# LPC55S16 register map
Vendor: nxp.com; File version: 1.0
CPU: CM33 r2p0, little endian, MPU, FPU, VTOR, 3 interrupt priority bits
Registers are 32-bit, read-write, reset 0x0 unless marked. A register's access mark holds for its fields unless they carry their own. Offsets are from the block's base; [hi:lo] are bit positions; {n}, {i} and the like mark numbered series; 'fields as' and 'values as' point back to an identical list.

## SYSCON
Base 0x40000000
0x00 MEMORYREMAP — Memory Remap control register
  [1:0] MAP — Select the location of the vector table :.
    0=ROM0 (Vector Table in ROM.); 1=RAM1 (Vector Table in RAM.); 2=FLASH0 (Vector Table in Flash.); 3=FLASH1 (Vector Table in Flash.)
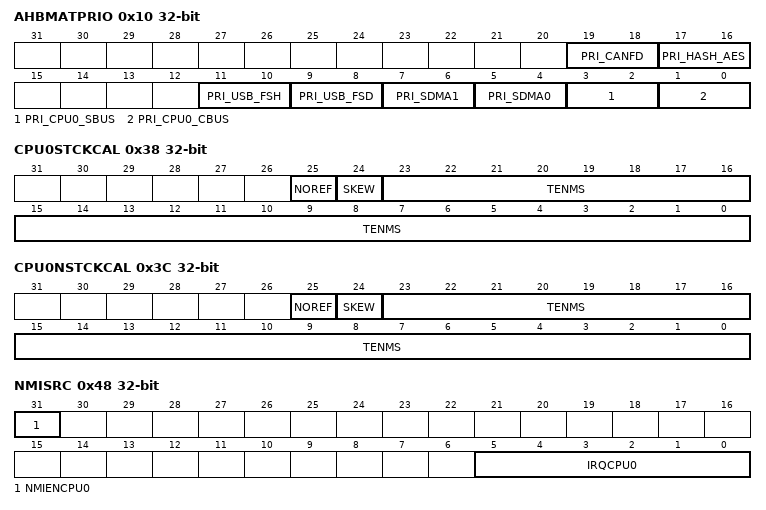
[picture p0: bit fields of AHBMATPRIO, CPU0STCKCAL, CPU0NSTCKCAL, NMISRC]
0x10 AHBMATPRIO — AHB Matrix priority control register Priority values are 3 = highest, 0 = lowest
  [19:18] PRI_CANFD — CANFD.
  [17:16] PRI_HASH_AES — HASH_AES.
  [11:10] PRI_USB_FSH — USB0-FS host.(USB0)
  [9:8] PRI_USB_FSD — USB0-FS Device.(USB0)
  [7:6] PRI_SDMA1 — DMA1 controller priority.
  [5:4] PRI_SDMA0 — DMA0 controller priority.
  [3:2] PRI_CPU0_SBUS — CPU0 S-AHB bus.
  [1:0] PRI_CPU0_CBUS — CPU0 C-AHB bus.
0x38 CPU0STCKCAL — System tick calibration for secure part of CPU0
  [25] NOREF — Indicates whether the device provides a reference clock to the processor: 0 = reference clock provided; 1 = no reference clock provided.
  [24] SKEW — Initial value for the Systick timer.
  [23:0] TENMS — Reload value for 10ms (100Hz) timing, subject to system clock skew errors. If the value reads as zero, the calibration value is not known.
0x3C CPU0NSTCKCAL — System tick calibration for non-secure part of CPU0
  [25] NOREF — Initial value for the Systick timer.
  [24] SKEW — Indicates whether the TENMS value is exact: 0 = TENMS value is exact; 1 = TENMS value is inexact, or not given.
  [23:0] TENMS — Reload value for 10 ms (100 Hz) timing, subject to system clock skew errors. If the value reads as zero, the calibration value is not known.
0x48 NMISRC — NMI Source Select
  [31] NMIENCPU0 — Write a 1 to this bit to enable the Non-Maskable Interrupt (NMI) source selected by IRQCPU0.
  [5:0] IRQCPU0 — The IRQ number of the interrupt that acts as the Non-Maskable Interrupt (NMI) for the CPU0, if enabled by NMIENCPU0.
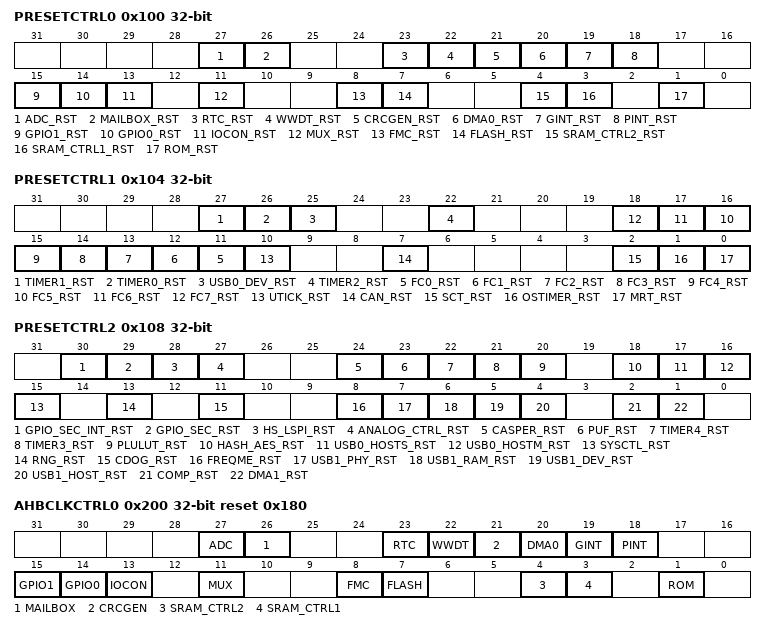
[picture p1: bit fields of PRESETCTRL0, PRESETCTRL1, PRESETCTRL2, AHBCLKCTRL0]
0x100 PRESETCTRL0 (PRESETCTRL view) — Peripheral reset control 0
  [all] fields
    0=RELEASED (Bloc is not reset.); 1=ASSERTED (Bloc is reset.)
  [27] ADC_RST — ADC reset control.
  [26] MAILBOX_RST — Inter CPU communication Mailbox reset control.
  [23] RTC_RST — Real Time Clock (RTC) reset control.
  [22] WWDT_RST — Watchdog Timer reset control.
  [21] CRCGEN_RST — CRCGEN reset control.
  [20] DMA0_RST — DMA0 reset control.
  [19] GINT_RST — Group interrupt (GINT) reset control.
  [18] PINT_RST — Pin interrupt (PINT) reset control.
  [15] GPIO1_RST — GPIO1 reset control.
  [14] GPIO0_RST — GPIO0 reset control.
  [13] IOCON_RST — I/O controller reset control.
  [11] MUX_RST — Input Mux reset control.
  [8] FMC_RST — FMC controller reset control.
  [7] FLASH_RST — Flash controller reset control.
  [4] SRAM_CTRL2_RST — SRAM Controller 2 reset control.
  [3] SRAM_CTRL1_RST — SRAM Controller 1 reset control.
  [1] ROM_RST — ROM reset control.
{0x100+4i} PRESETCTRLX{i} (PRESETCTRL view) (i=0..2) — Peripheral reset control register
  [31:0] DATA — Data array value
0x104 PRESETCTRL1 (reset mask 0xDE57FC47) (PRESETCTRL view) — Peripheral reset control 1
  [all] fields
    0=RELEASED (Bloc is not reset.); 1=ASSERTED (Bloc is reset.)
  [27] TIMER1_RST — Timer 1 reset control.
  [26] TIMER0_RST — Timer 0 reset control.
  [25] USB0_DEV_RST — USB0-FS DEV reset control.
  [22] TIMER2_RST — Timer 2 reset control.
  [n+11] FC{n}_RST (n=0..7) — FC{n} reset control.
  [10] UTICK_RST — UTICK reset control.
  [7] CAN_RST — CAN reset control.
  [2] SCT_RST — SCT reset control.
  [1] OSTIMER_RST — OS Event Timer reset control.
  [0] MRT_RST — MRT reset control.
0x108 PRESETCTRL2 (reset mask 0x7FFF77FE) (PRESETCTRL view) — Peripheral reset control 2
  [all] fields
    0=RELEASED (Bloc is not reset.); 1=ASSERTED (Bloc is reset.)
  [30] GPIO_SEC_INT_RST — GPIO secure int reset control.
  [29] GPIO_SEC_RST — GPIO secure reset control.
  [28] HS_LSPI_RST — HS LSPI reset control.
  [27] ANALOG_CTRL_RST — analog control reset control.
  [24] CASPER_RST — Casper reset control.
  [23] PUF_RST — PUF reset control reset control.
  [22] TIMER4_RST — Timer 4 reset control.
  [21] TIMER3_RST — Timer 3 reset control.
  [20] PLULUT_RST — PLU LUT reset control.
  [18] HASH_AES_RST — HASH_AES reset control.
  [17] USB0_HOSTS_RST — USB0-FS Host Slave reset control.
  [16] USB0_HOSTM_RST — USB0-FS Host Master reset control.
  [15] SYSCTL_RST — SYSCTL Block reset.
  [13] RNG_RST — RNG reset control.
  [11] CDOG_RST — Code Watchdog reset control.
  [8] FREQME_RST — Frequency meter reset control.
  [7] USB1_PHY_RST — USB1-HS PHY reset control.
  [6] USB1_RAM_RST — USB1-HS RAM reset control.
  [5] USB1_DEV_RST — USB1-HS dev reset control.
  [4] USB1_HOST_RST — USB1-HS Host reset control.
  [2] COMP_RST — Comparator reset control.
  [1] DMA1_RST — DMA1 reset control.
{0x120+4i} PRESETCTRLSET[{i}] (i=0..2) — Peripheral reset control set register
  [31:0] DATA — Data array value
{0x140+4i} PRESETCTRLCLR[{i}] (i=0..2) — Peripheral reset control clear register
  [31:0] DATA — Data array value
0x160 SWR_RESET wo — generate a software_reset
  [31:0] SWR_RESET — Write 0x5A00_0001 to generate a software_reset.
    0=RELEASED (Bloc is not reset.); 0x5A000001=ASSERTED (Generate a software reset.)
0x200 AHBCLKCTRL0 reset 0x180 (AHBCLKCTRL view) — AHB Clock control 0
  [all] fields
    0=DISABLE (Disable Clock.); 1=ENABLE (Enable Clock.)
  [27] ADC — Enables the clock for the ADC.
  [26] MAILBOX — Enables the clock for the Inter CPU communication Mailbox.
  [23] RTC — Enables the clock for the Real Time Clock (RTC).
  [22] WWDT — Enables the clock for the Watchdog Timer.
  [21] CRCGEN — Enables the clock for the CRCGEN.
  [20] DMA0 — Enables the clock for the DMA0.
  [19] GINT — Enables the clock for the Group interrupt (GINT).
  [18] PINT — Enables the clock for the Pin interrupt (PINT).
  [15] GPIO1 — Enables the clock for the GPIO1.
  [14] GPIO0 — Enables the clock for the GPIO0.
  [13] IOCON — Enables the clock for the I/O controller.
  [11] MUX — Enables the clock for the Input Mux.
  [8] FMC — Enables the clock for the FMC controller.
  [7] FLASH — Enables the clock for the Flash controller.
  [4] SRAM_CTRL2 — Enables the clock for the SRAM Controller 2.
  [3] SRAM_CTRL1 — Enables the clock for the SRAM Controller 1.
  [1] ROM — Enables the clock for the ROM.
{0x200+4i} AHBCLKCTRLX{i} (AHBCLKCTRL view) (i=0..2) — Peripheral reset control register
  [31:0] DATA — Data array value
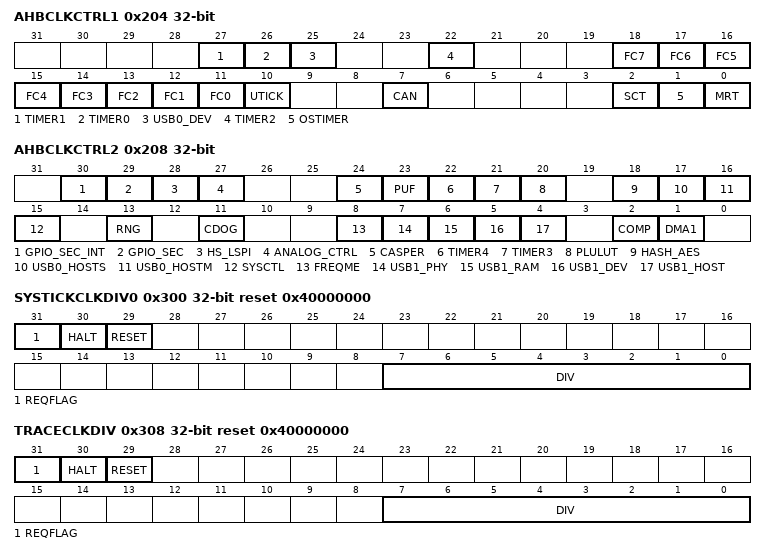
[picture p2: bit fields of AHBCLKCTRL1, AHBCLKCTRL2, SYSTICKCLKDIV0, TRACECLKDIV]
0x204 AHBCLKCTRL1 (reset mask 0xDE57FC47) (AHBCLKCTRL view) — AHB Clock control 1
  [all] fields
    0=DISABLE (Disable Clock.); 1=ENABLE (Enable Clock.)
  [27] TIMER1 — Enables the clock for the Timer 1.
  [26] TIMER0 — Enables the clock for the Timer 0.
  [25] USB0_DEV — Enables the clock for the USB0-FS device.
  [22] TIMER2 — Enables the clock for the Timer 2.
  [n+11] FC{n} (n=0..7) — Enables the clock for the FC{n}.
  [10] UTICK — Enables the clock for the UTICK.
  [7] CAN — Enables the clock for the CAN.
  [2] SCT — Enables the clock for the SCT.
  [1] OSTIMER — Enables the clock for the OS Event Timer.
  [0] MRT — Enables the clock for the MRT.
0x208 AHBCLKCTRL2 (reset mask 0x7FFF77FE) (AHBCLKCTRL view) — AHB Clock control 2
  [all] fields
    0=DISABLE (Disable Clock.); 1=ENABLE (Enable Clock.)
  [30] GPIO_SEC_INT — Enables the clock for the GPIO secure int.
  [29] GPIO_SEC — Enables the clock for the GPIO secure.
  [28] HS_LSPI — Enables the clock for the HS LSPI.
  [27] ANALOG_CTRL — Enables the clock for the analog control.
  [24] CASPER — Enables the clock for the Casper.
  [23] PUF — Enables the clock for the PUF reset control.
  [22] TIMER4 — Enables the clock for the Timer 4.
  [21] TIMER3 — Enables the clock for the Timer 3.
  [20] PLULUT — Enables the clock for the PLU LUT.
  [18] HASH_AES — Enables the clock for the HASH_AES.
  [17] USB0_HOSTS — Enables the clock for the USB0-FS Host Slave.
  [16] USB0_HOSTM — Enables the clock for the USB0-FS Host Master.
  [15] SYSCTL — SYSCTL block clock.
  [13] RNG — Enables the clock for the RNG.
  [11] CDOG — Enables the clock for the code watchdog.
  [8] FREQME — Enables the clock for the Frequency meter.
  [7] USB1_PHY — Enables the clock for the USB1-HS PHY.
  [6] USB1_RAM — Enables the clock for the USB1-HS RAM.
  [5] USB1_DEV — Enables the clock for the USB1-HS device.
  [4] USB1_HOST — Enables the clock for the USB1-HS Host.
  [2] COMP — Enables the clock for the Comparator.
  [1] DMA1 — Enables the clock for the DMA1.
{0x220+4i} AHBCLKCTRLSET[{i}] (i=0..2) — Peripheral reset control register
  [31:0] DATA — Data array value
{0x240+4i} AHBCLKCTRLCLR[{i}] (i=0..2) — Peripheral reset control register
  [31:0] DATA — Data array value
0x260 SYSTICKCLKSEL0 reset 0x7 (SYSTICKCLKSEL view) — System Tick Timer for CPU0 source select
  [2:0] SEL — System Tick Timer for CPU0 source select.
    0=ENUM_0x0 (System Tick 0 divided clock.); 1=ENUM_0x1 (FRO 1MHz clock.); 2=ENUM_0x2 (Oscillator 32 kHz clock.); {v}=ENUM_{0x0+v} (No clock.) (v=3..7)
0x260 SYSTICKCLKSELX0 (SYSTICKCLKSEL view) — Peripheral reset control register
  [31:0] DATA — Data array value
0x268 TRACECLKSEL reset 0x7 — Trace clock source select
  [2:0] SEL — Trace clock source select.
    0=ENUM_0x0 (Trace divided clock.); 1=ENUM_0x1 (FRO 1MHz clock.); 2=ENUM_0x2 (Oscillator 32 kHz clock.); {v}=ENUM_{0x0+v} (No clock.) (v=3..7)
{0x26C+4i} CTIMERCLKSEL{i} reset 0x7 (CTIMERCLKSEL view) (i=0..4) — CTimer {i} clock source select
  [2:0] SEL — CTimer {i} clock source select.
    0=ENUM_0x0 (Main clock.); 1=ENUM_0x1 (PLL0 clock.); 2=ENUM_0x2 (No clock.); 3=ENUM_0x3 (FRO 96 MHz clock.); 4=ENUM_0x4 (FRO 1MHz clock.); 5=ENUM_0x5 (MCLK clock.); 6=ENUM_0x6 (Oscillator 32kHz clock.); 7=ENUM_0x7 (No clock.)
{0x26C+4i} CTIMERCLKSELX{i} (CTIMERCLKSEL view) (i=0..4) — Peripheral reset control register
  [31:0] DATA — Data array value
0x280 MAINCLKSELA — Main clock A source select
  [2:0] SEL — Main clock A source select.
    0=ENUM_0x0 (FRO 12 MHz clock.); 1=ENUM_0x1 (CLKIN clock.); 2=ENUM_0x2 (FRO 1MHz clock.); 3=ENUM_0x3 (FRO 96 MHz clock.)
0x284 MAINCLKSELB — Main clock source select
  [2:0] SEL — Main clock source select.
    0=ENUM_0x0 (Main Clock A.); 1=ENUM_0x1 (PLL0 clock.); 2=ENUM_0x2 (PLL1 clock.); 3=ENUM_0x3 (Oscillator 32 kHz clock.)
0x288 CLKOUTSEL reset 0xF — CLKOUT clock source select
  [3:0] SEL — CLKOUT clock source select.
    0=ENUM_0x0 (Main clock.); 1=ENUM_0x1 (PLL0 clock.); 2=ENUM_0x2 (CLKIN clock.); 3=ENUM_0x3 (FRO 96 MHz clock.); 4=ENUM_0x4 (FRO 1MHz clock.); 5=ENUM_0x5 (PLL1 clock.); 6=ENUM_0x6 (Oscillator 32kHz clock.); 7=ENUM_0x7 (No clock.); {v}=ENUM_{0x0+v} (No clock.) (v=12..15)
0x290 PLL0CLKSEL reset 0x7 — PLL0 clock source select
  [2:0] SEL — PLL0 clock source select.
    0=ENUM_0x0 (FRO 12 MHz clock.); 1=ENUM_0x1 (CLKIN clock.); 2=ENUM_0x2 (FRO 1MHz clock.); 3=ENUM_0x3 (Oscillator 32kHz clock.); {v}=ENUM_{0x0+v} (No clock.) (v=4..7)
0x294 PLL1CLKSEL reset 0x7 — PLL1 clock source select
  [2:0] SEL — PLL1 clock source select.
    values as PLL0CLKSEL.SEL
0x2A0 CANCLKSEL reset 0x7 — CAN clock source select
  [2:0] SEL — CAN clock source select.
    0=ENUM_0x0 (CAN divided clock.); 1=ENUM_0x1 (FRO 1MHz clock.); 2=ENUM_0x2 (Oscillator 32 kHz clock.); {v}=ENUM_{0x0+v} (No clock.) (v=3..7)
0x2A4 ADCCLKSEL reset 0x7 — ADC clock source select
  [2:0] SEL — ADC clock source select.
    0=ENUM_0x0 (Main clock.); 1=ENUM_0x1 (PLL0 clock.); 2=ENUM_0x2 (FRO 96 MHz clock.); 4=ENUM_0x4 (Xtal clock coming directly.); 5=ENUM_0x5 (No clock.); 6=ENUM_0x6 (No clock.); 7=ENUM_0x7 (No clock.)
0x2A8 USB0CLKSEL reset 0x7 — FS USB clock source select
  [2:0] SEL — FS USB clock source select.
    0=ENUM_0x0 (Main clock.); 1=ENUM_0x1 (PLL0 clock.); 2=ENUM_0x2 (No clock.); 3=ENUM_0x3 (FRO 96 MHz clock.); 4=ENUM_0x4 (No clock.); 5=ENUM_0x5 (PLL1 clock.); 6=ENUM_0x6 (No clock.); 7=ENUM_0x7 (No clock.)
0x2AC CLK32KCLKSEL — clock low speed source select for HS USB.
  [3] SEL
    0=ENUM_0x0 (Oscillator 32 kHz clock.); 1=ENUM_0x1 (FRO1MHz_divided clock.)
{0x2B0+4i} FCCLKSEL{i} reset 0x7 (FCCLKSEL view) (i=0..7) — Flexcomm Interface {i} clock source select for Fractional Rate Divider
  [2:0] SEL — Flexcomm Interface {i} clock source select for Fractional Rate Divider.
    0=ENUM_0x0 (Main clock.); 1=ENUM_0x1 (system PLL divided clock.); 2=ENUM_0x2 (FRO 12 MHz clock.); 3=ENUM_0x3 (FRO 96 MHz clock.); 4=ENUM_0x4 (FRO 1MHz clock.); 5=ENUM_0x5 (MCLK clock.); 6=ENUM_0x6 (Oscillator 32 kHz clock.); 7=ENUM_0x7 (No clock.)
{0x2B0+4i} FCCLKSELX{i} (FCCLKSEL view) (i=0..7) — Peripheral reset control register
  [31:0] DATA — Data array value
0x2D0 HSLSPICLKSEL reset 0x7 — HS LSPI clock source select
  [2:0] SEL — HS LSPI clock source select.
    0=ENUM_0x0 (Main clock.); 1=ENUM_0x1 (system PLL divided clock.); 2=ENUM_0x2 (FRO 12 MHz clock.); 3=ENUM_0x3 (FRO 96 MHz clock.); 4=ENUM_0x4 (FRO 1MHz clock.); 5=ENUM_0x5 (No clock.); 6=ENUM_0x6 (Oscillator 32 kHz clock.); 7=ENUM_0x7 (No clock.)
0x2E0 MCLKCLKSEL reset 0x7 — MCLK clock source select
  [2:0] SEL — MCLK clock source select.
    0=ENUM_0x0 (FRO 96 MHz clock.); 1=ENUM_0x1 (PLL0 clock.); {v}=ENUM_{0x0+v} (No clock.) (v=4..7)
0x2F0 SCTCLKSEL reset 0x7 — SCTimer/PWM clock source select
  [2:0] SEL — SCTimer/PWM clock source select.
    0=ENUM_0x0 (Main clock.); 1=ENUM_0x1 (PLL0 clock.); 2=ENUM_0x2 (CLKIN clock.); 3=ENUM_0x3 (FRO 96 MHz clock.); 4=ENUM_0x4 (No clock.); 5=ENUM_0x5 (MCLK clock.); 6=ENUM_0x6 (No clock.); 7=ENUM_0x7 (No clock.)
0x300 SYSTICKCLKDIV0 reset 0x40000000 — System Tick Timer divider for CPU0
  [31] REQFLAG ro — Divider status flag.
    0=STABLE (Divider clock is stable.); 1=ONGOING (Clock frequency is not stable.)
  [30] HALT — Halts the divider counter.
    0=RUN (Divider clock is running.); 1=HALT (Divider clock is stoped.)
  [29] RESET wo — Resets the divider counter.
    0=RELEASED (Divider is not reset.); 1=ASSERTED (Divider is reset.)
  [7:0] DIV — Clock divider value.
0x308 TRACECLKDIV reset 0x40000000 — TRACE clock divider
  fields as SYSTICKCLKDIV0
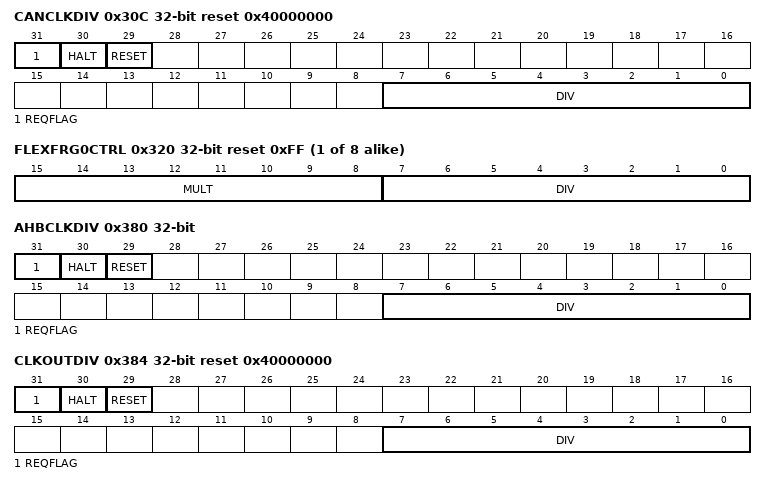
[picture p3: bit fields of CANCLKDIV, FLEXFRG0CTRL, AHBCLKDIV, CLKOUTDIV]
0x30C CANCLKDIV reset 0x40000000 — CAN clock divider
  fields as SYSTICKCLKDIV0
{0x320+4i} FLEXFRG{i}CTRL reset 0xFF (FLEXFRGCTRL view) (i=0..7) — Fractional rate divider for flexcomm {i}
  [15:8] MULT — Numerator of the fractional rate divider.
  [7:0] DIV — Denominator of the fractional rate divider.
{0x320+4i} FLEXFRGXCTRL{i} (FLEXFRGCTRL view) (i=0..7) — Peripheral reset control register
  [31:0] DATA — Data array value
0x380 AHBCLKDIV — System clock divider
  fields as SYSTICKCLKDIV0
0x384 CLKOUTDIV reset 0x40000000 — CLKOUT clock divider
  fields as SYSTICKCLKDIV0
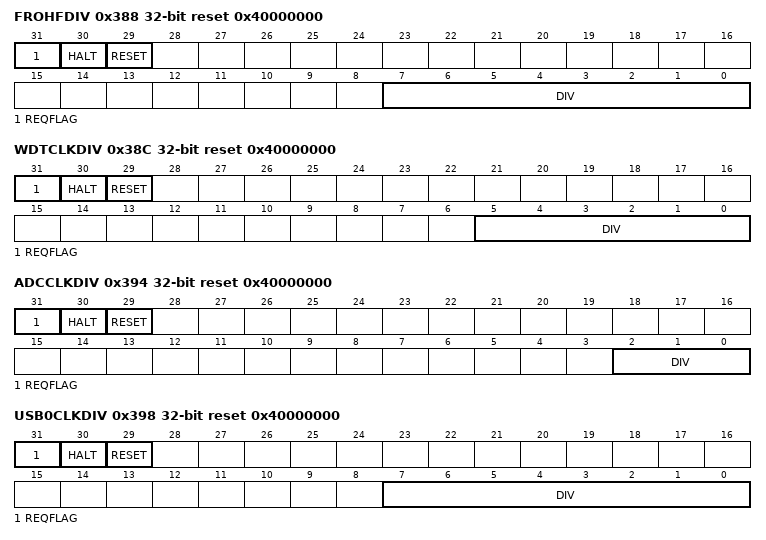
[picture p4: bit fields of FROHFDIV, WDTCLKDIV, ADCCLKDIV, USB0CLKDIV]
0x388 FROHFDIV reset 0x40000000 — FRO_HF (96MHz) clock divider
  fields as SYSTICKCLKDIV0
0x38C WDTCLKDIV reset 0x40000000 — WDT clock divider
  [31] REQFLAG ro — Divider status flag.
    values as SYSTICKCLKDIV0.REQFLAG
  [30] HALT — Halts the divider counter.
    values as SYSTICKCLKDIV0.HALT
  [29] RESET wo — Resets the divider counter.
    values as SYSTICKCLKDIV0.RESET
  [5:0] DIV — Clock divider value.
0x394 ADCCLKDIV reset 0x40000000 — ADC clock divider
  [31] REQFLAG ro — Divider status flag.
    values as SYSTICKCLKDIV0.REQFLAG
  [30] HALT — Halts the divider counter.
    values as SYSTICKCLKDIV0.HALT
  [29] RESET wo — Resets the divider counter.
    values as SYSTICKCLKDIV0.RESET
  [2:0] DIV — Clock divider value.
0x398 USB0CLKDIV reset 0x40000000 — USB0-FS Clock divider
  fields as SYSTICKCLKDIV0
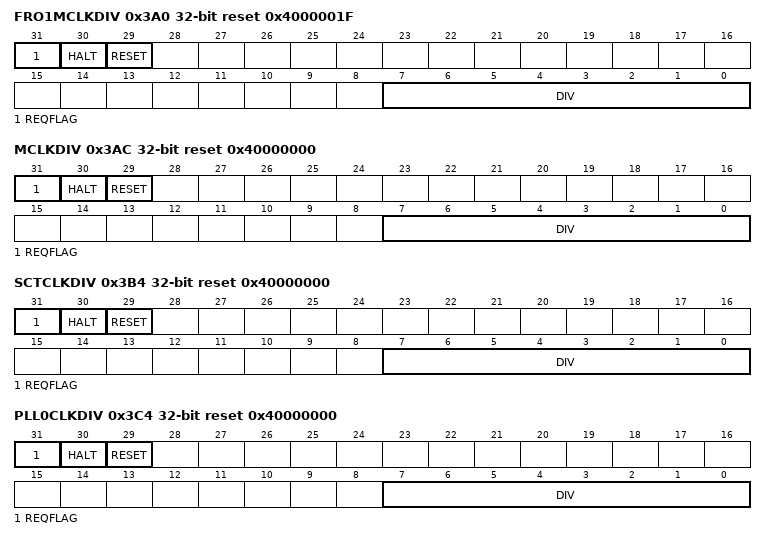
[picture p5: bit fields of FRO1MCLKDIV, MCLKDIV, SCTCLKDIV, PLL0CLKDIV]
0x3A0 FRO1MCLKDIV reset 0x4000001F — FRO1MHz Clock divider (FRO1M_divided)
  fields as SYSTICKCLKDIV0
0x3AC MCLKDIV reset 0x40000000 — I2S MCLK clock divider
  fields as SYSTICKCLKDIV0
0x3B4 SCTCLKDIV reset 0x40000000 — SCT/PWM clock divider
  fields as SYSTICKCLKDIV0
0x3C4 PLL0CLKDIV reset 0x40000000 — PLL0 clock divider
  fields as SYSTICKCLKDIV0
0x3FC CLOCKGENUPDATELOCKOUT — Control clock configuration registers access (like xxxDIV, xxxSEL)
  [31:0] CLOCKGENUPDATELOCKOUT — Control clock configuration registers access (for example, xxxDIV, xxxSEL).
    0=FREEZE (all hardware clock configruration are freeze.); 1=ENABLE (update all clock configuration.)
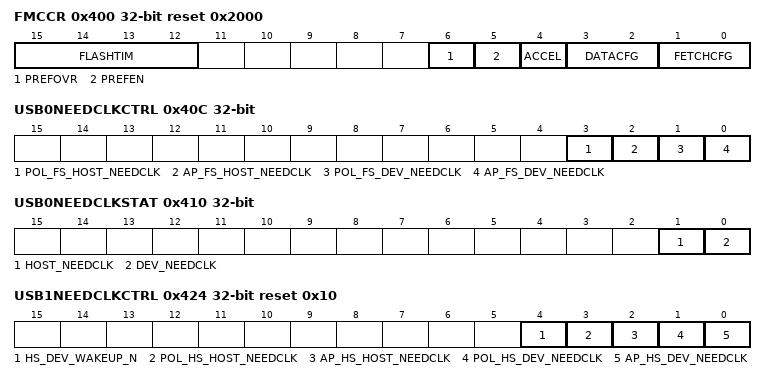
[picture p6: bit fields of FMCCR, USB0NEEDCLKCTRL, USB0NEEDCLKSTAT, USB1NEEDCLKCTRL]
0x400 FMCCR reset 0x2000 — FMC configuration register
  [15:12] FLASHTIM — Flash memory access time.
    0=1 system clock flash access time (for system clock rates up to 11 MHz); 1=2 system clocks flash access time (for system clock rates up to 22 MHz); 2=3 system clocks flash access time (for system clock rates up to 33 MHz); 3=4 system clocks flash access time (for system clock rates up to 44 MHz); 4=5 system clocks flash access time (for system clock rates up to 55 MHz); 5=6 system clocks flash access time (for system clock rates up to 66 MHz); 6=7 system clocks flash access time (for system clock rates up to 84 MHz); 7=8 system clocks flash access time (for system clock rates up to 104 MHz); 8=9 system clocks flash access time (for system clock rates up to 119 MHz); 9=10 system clocks flash access time (for system clock rates up to 129 MHz); 10=11 system clocks flash access time (for system clock rates up to 144 MHz); 11=12 system clocks flash access time (for system clock rates up to 150 MHz)
  [6] PREFOVR — Prefetch override.
    0=NORMAL (Any previously initiated prefetch will be completed.); 1=OVERRIDE (Any previously initiated prefetch will be aborted, and the next flash line following the current execution address will be prefetched if not already buffered.)
  [5] PREFEN — Prefetch enable.
    0=DISABLE (No instruction prefetch is performed.); 1=ENABLE (Instruction prefetch is enabled.)
  [4] ACCEL — Acceleration enable.
    0=DISABLE (Flash acceleration is disabled.); 1=ENABLE (Flash acceleration is enabled.)
  [3:2] DATACFG — Data read configuration.
    0=NOBUF (Data accesses from flash are not buffered.); 1=ONEBUF (One buffer is used for all data accesses.); 2=ALLBUF (All buffers can be used for data accesses.)
  [1:0] FETCHCFG — Instruction fetch configuration.
    0=NOBUF (Instruction fetches from flash are not buffered.); 1=ONEBUF (One buffer is used for all instruction fetches.); 2=ALLBUF (All buffers may be used for instruction fetches.)
0x40C USB0NEEDCLKCTRL — USB0-FS need clock control
  [3] POL_FS_HOST_NEEDCLK — USB0-FS Host USB0_NEEDCLK polarity for triggering the USB0-FS wake-up interrupt:.
    0=FALLING (Falling edge of device USB0_NEEDCLK triggers wake-up.); 1=RISING (Rising edge of device USB0_NEEDCLK triggers wake-up.)
  [2] AP_FS_HOST_NEEDCLK — USB0-FS Host USB0_NEEDCLK signal control:.
    0=HW_CTRL (Under hardware control.); 1=FORCED (Forced high.)
  [1] POL_FS_DEV_NEEDCLK — USB0-FS Device USB0_NEEDCLK polarity for triggering the USB0-FS wake-up interrupt:.
    values as POL_FS_HOST_NEEDCLK
  [0] AP_FS_DEV_NEEDCLK — USB0-FS Device USB0_NEEDCLK signal control:.
    0=HW_CTRL (Under hardware control.); 1=FORCED (Forced high.)
0x410 USB0NEEDCLKSTAT — USB0-FS need clock status
  [1] HOST_NEEDCLK ro — USB0-FS Host USB0_NEEDCLK signal status:.
    0=LOW (USB0-FS Host clock is low.); 1=HIGH (USB0-FS Host clock is high.)
  [0] DEV_NEEDCLK ro — USB0-FS Device USB0_NEEDCLK signal status:.
    0=LOW (USB0-FS Device clock is low.); 1=HIGH (USB0-FS Device clock is high.)
0x41C FMCFLUSH wo — FMCflush control
  [0] FLUSH — Flush control
    0=NO_FLUSH (No action is performed.); 1=FLUSH (Flush the FMC buffer contents.)
0x420 MCLKIO — MCLK control
  [0] MCLKIO — MCLK control.
    0=INPUT (input mode.); 1=OUTPUT (output mode.)
0x424 USB1NEEDCLKCTRL reset 0x10 — USB1-HS need clock control
  [4] HS_DEV_WAKEUP_N — Software override of device controller PHY wake up logic.
    0=FORCE_WUP (Forces USB1_PHY to wake-up.); 1=NORMAL_WUP (Normal USB1_PHY behavior.)
  [3] POL_HS_HOST_NEEDCLK — USB1-HS host need clock polarity for triggering the USB1_NEEDCLK wake-up interrupt.
    0=FALLING (Falling edge of HOST_NEEDCLK triggers wake-up.); 1=RISING (Rising edge of HOST_NEEDCLK triggers wake-up.)
  [2] AP_HS_HOST_NEEDCLK — USB1-HS Host need clock signal control:
    0=HW_CTRL (HOST_NEEDCLK is under hardware control.); 1=FORCED (HOST_NEEDCLK is forced high.)
  [1] POL_HS_DEV_NEEDCLK — USB1-HS device need clock polarity for triggering the USB1_NEEDCLK wake-up interrupt:
    0=FALLING (Falling edge of DEV_NEEDCLK triggers wake-up.); 1=RISING (Rising edge of DEV_NEEDCLK triggers wake-up.)
  [0] AP_HS_DEV_NEEDCLK — USB1-HS Device need_clock signal control:
    values as AP_HS_HOST_NEEDCLK
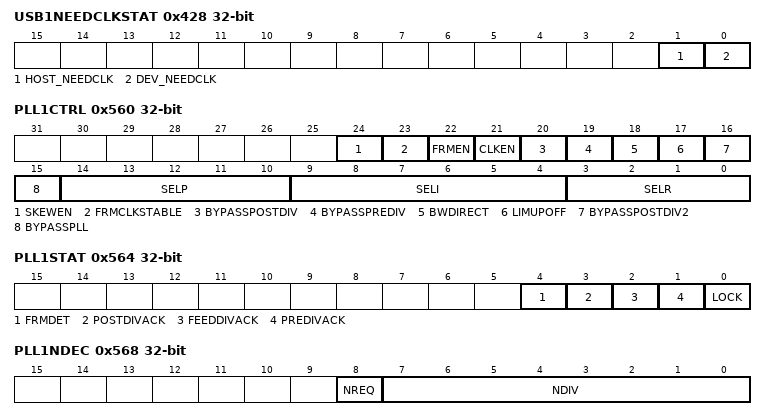
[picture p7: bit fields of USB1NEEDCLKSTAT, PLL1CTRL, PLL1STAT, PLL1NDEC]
0x428 USB1NEEDCLKSTAT — USB1-HS need clock status
  [1] HOST_NEEDCLK ro — USB1-HS Host need_clock signal status:.
    0=LOW (HOST_NEEDCLK is low.); 1=HIGH (HOST_NEEDCLK is high.)
  [0] DEV_NEEDCLK ro — USB1-HS Device need_clock signal status:.
    0=LOW (DEV_NEEDCLK is low.); 1=HIGH (DEV_NEEDCLK is high.)
0x440 FLASHREMAP_SIZE — This 32-bit register contains the size of the image to remap, in bytes. The 12 LSBs are ignored, so the size granularity is 4KB.
0x444 FLASHREMAP_SIZE_DP — This 32-bit register is a duplicate of FLASHREMAPSIZE for increased security.
  [31:0] FLASHREMAP_SIZE
0x448 FLASHREMAP_OFFSET — This 32-bit register contains the offset by which the image is to be remapped. The 12 LSBs are ignored, so the remap granularity is 4KB.
0x44C FLASHREMAP_OFFSET_DP — This 32-bit register is a duplicate of FLASHREMAPOFFSET for increased security.
  [31:0] FLASHREMAP_OFFSET
0x45C FLASHREMAP_LOCK reset 0xC33CA55A — Control write access to FLASHREMAP_SIZE and FLASHREMAP_OFFSET registers.
  [31:0] LOCK — Control write access to FLASHREMAP_SIZE and FLASHREMAP_OFFSET registers. Any value other than 0xC33CA55A and 0x3CC35AA5 does not modify the state.
    0x3CC35AA5=UNLOCK (Write access to 4 registers FLASHREMAP_SIZE* and FLASHREMAP_OFFSET* is unlocked.); 0xC33CA55A=LOCK (Write access to 4 registers FLASHREMAP_SIZE* and FLASHREMAP_OFFSET* is locked.)
0x470 CASPER_CTRL — Control CASPER integration.
  [0] INTERLEAVE — Control RAM access for RAMX0 and RAMX1.
    0=NORMAL (RAM access to RAMX0 and RAMX1 is consecutive.); 1=INTERLEAVE (RAM access to RAMX0 and RAMX1 is interleaved.)
0x560 PLL1CTRL — PLL1 550m control
  [24] SKEWEN — Skew mode.
    0=DISABLE (skewmode is disable.); 1=ENABLE (skewmode is enable.)
  [23] FRMCLKSTABLE — free running mode clockstable: Warning: Only make frm_clockstable = 1 after the PLL output frequency is stable.
  [22] FRMEN — 1: free running mode.
  [21] CLKEN — enable the output clock.
    0=DISABLE (Disable the output clock.); 1=ENABLE (Enable the output clock.)
  [20] BYPASSPOSTDIV — bypass of the post-divider.
    0=USED (use the post-divider.); 1=BYPASSED (bypass of the post-divider.)
  [19] BYPASSPREDIV — bypass of the pre-divider.
    0=USED (use the pre-divider.); 1=BYPASSED (bypass of the pre-divider.)
  [18] BWDIRECT — control of the bandwidth of the PLL.
    0=SYNC (the bandwidth is changed synchronously with the feedback-divider.); 1=DIRECT (modify the bandwidth of the PLL directly.)
  [17] LIMUPOFF — limup_off = 1 in spread spectrum and fractional PLL applications.
  [16] BYPASSPOSTDIV2 — bypass of the divide-by-2 divider in the post-divider.
    0=USED (use the divide-by-2 divider in the post-divider.); 1=BYPASSED (bypass of the divide-by-2 divider in the post-divider.)
  [15] BYPASSPLL — Bypass PLL input clock is sent directly to the PLL output (default).
    0=USED (use PLL.); 1=BYPASSED (PLL input clock is sent directly to the PLL output.)
  [14:10] SELP — Bandwidth select P value.
  [9:4] SELI — Bandwidth select I value.
  [3:0] SELR — Bandwidth select R value.
0x564 PLL1STAT — PLL1 550m status
  [4] FRMDET ro — free running detector output (active high).
  [3] POSTDIVACK ro — post-divider ratio change acknowledge.
  [2] FEEDDIVACK ro — feedback divider ratio change acknowledge.
  [1] PREDIVACK ro — pre-divider ratio change acknowledge.
  [0] LOCK ro — lock detector output (active high) Warning: The lock signal is only reliable between fref[2] :100 kHz to 20 MHz.
0x568 PLL1NDEC — PLL1 550m N divider
  [8] NREQ — pre-divider ratio change request.
  [7:0] NDIV — pre-divider divider ratio (N-divider).
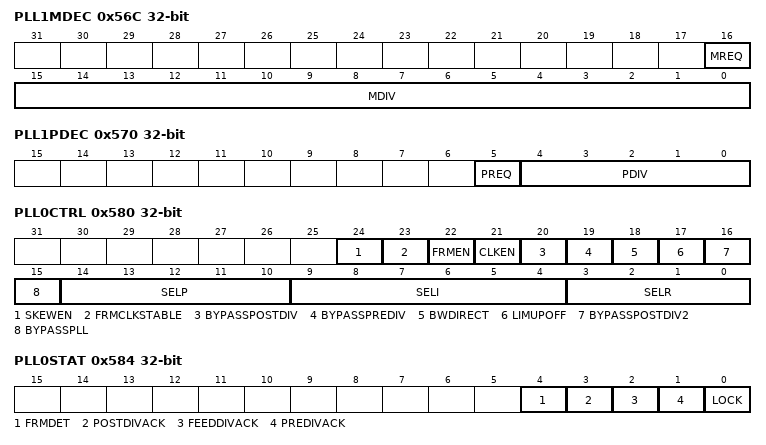
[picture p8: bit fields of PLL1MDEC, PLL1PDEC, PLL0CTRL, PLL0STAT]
0x56C PLL1MDEC — PLL1 550m M divider
  [16] MREQ — feedback ratio change request.
  [15:0] MDIV — feedback divider divider ratio (M-divider).
0x570 PLL1PDEC — PLL1 550m P divider
  [5] PREQ — feedback ratio change request.
  [4:0] PDIV — post-divider divider ratio (P-divider)
0x580 PLL0CTRL — PLL0 550m control
  [24] SKEWEN — skew mode.
    0=DISABLE (skew mode is disable.); 1=ENABLE (skew mode is enable.)
  [23] FRMCLKSTABLE — free running mode clockstable: Warning: Only make frm_clockstable =1 after the PLL output frequency is stable.
  [22] FRMEN — free running mode.
    0=DISABLE (free running mode is disable.); 1=ENABLE (free running mode is enable.)
  [21] CLKEN — enable the output clock.
    0=DISABLE (disable the output clock.); 1=ENABLE (enable the output clock.)
  [20] BYPASSPOSTDIV — bypass of the post-divider.
    values as PLL1CTRL.BYPASSPOSTDIV
  [19] BYPASSPREDIV — bypass of the pre-divider.
    values as PLL1CTRL.BYPASSPREDIV
  [18] BWDIRECT — Control of the bandwidth of the PLL.
    values as PLL1CTRL.BWDIRECT
  [17] LIMUPOFF — limup_off = 1 in spread spectrum and fractional PLL applications.
  [16] BYPASSPOSTDIV2 — bypass of the divide-by-2 divider in the post-divider.
    values as PLL1CTRL.BYPASSPOSTDIV2
  [15] BYPASSPLL — Bypass PLL input clock is sent directly to the PLL output (default).
    0=USED (use PLL.); 1=BYPASSED (Bypass PLL input clock is sent directly to the PLL output.)
  [14:10] SELP — Bandwidth select P value.
  [9:4] SELI — Bandwidth select I value.
  [3:0] SELR — Bandwidth select R value.
0x584 PLL0STAT — PLL0 550m status
  fields as PLL1STAT
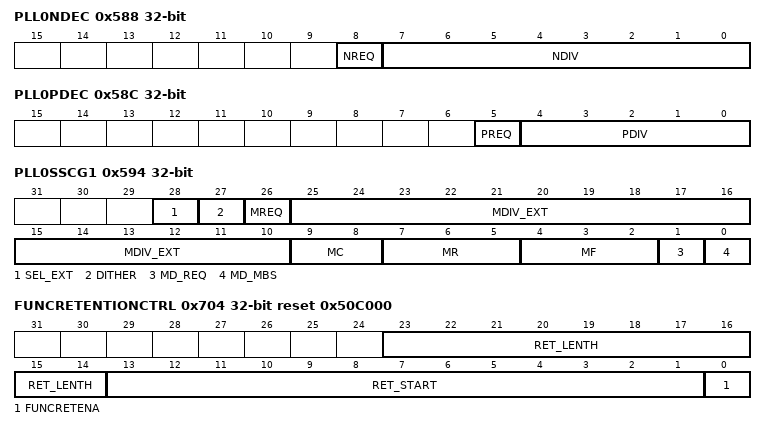
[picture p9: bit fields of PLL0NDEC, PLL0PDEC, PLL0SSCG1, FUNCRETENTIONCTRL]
0x588 PLL0NDEC — PLL0 550m N divider
  fields as PLL1NDEC
0x58C PLL0PDEC — PLL0 550m P divider
  fields as PLL1PDEC
0x590 PLL0SSCG0 — PLL0 Spread Spectrum Wrapper control register 0
  [31:0] MD_LBS — input word of the wrapper bit 31 to 0.
0x594 PLL0SSCG1 — PLL0 Spread Spectrum Wrapper control register 1
  [28] SEL_EXT — to select mdiv_ext and mreq_ext sel_ext = 0: mdiv ~ md[32:0], mreq = 1 sel_ext = 1 : mdiv = mdiv_ext, mreq = mreq_ext.
  [27] DITHER — dithering between two modulation frequencies in a random way or in a pseudo random way (white noise), in order to decrease the probability that the modulated waveform will occur with the same phase on a particular point on the screen.
  [26] MREQ — to select an external mreq value.
  [25:10] MDIV_EXT — to select an external mdiv value.
  [9:8] MC — modulation waveform control Compensation for low pass filtering of the PLL to get a triangular modulation at the output of the PLL, giving a flat frequency spectrum.
  [7:5] MR — programmable frequency modulation depth Dfmodpk-pk = Fref*kss/Fcco = kss/(2*md[32:25]dec) mr[2:0] = 000 => kss = 0 (no spread spectrum) mr[2:0] = 001 => kss ~ 1 mr[2:0] = 010 => kss ~ 1.
  [4:2] MF — programmable modulation frequency fm = Fref/Nss mf[2:0] = 000 => Nss=512 (fm ~ 3.
  [1] MD_REQ — md change request.
  [0] MD_MBS — input word of the wrapper bit 32.
0x704 FUNCRETENTIONCTRL reset 0x50C000 — Functional retention control register
  [23:14] RET_LENTH — lenth of Scan chains to save.
  [13:1] RET_START — Start address divided by 4 inside SRAMX bank.
  [0] FUNCRETENA — functional retention in power down only.
    0=DISABLE (disable functional retention.); 1=ENABLE (enable functional retention.)
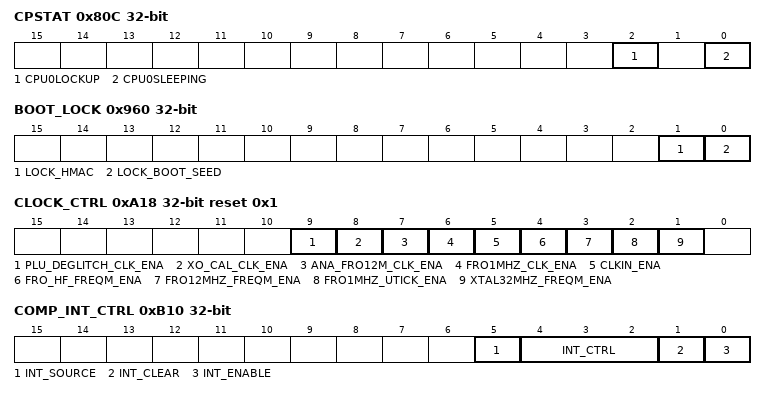
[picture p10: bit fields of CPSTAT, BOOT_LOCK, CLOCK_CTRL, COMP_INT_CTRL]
0x80C CPSTAT — CPU Status
  [2] CPU0LOCKUP ro — The CPU0 lockup state.
    0=AWAKE (the CPU is not in lockup.); 1=SLEEPING (the CPU is in lockup.)
  [0] CPU0SLEEPING ro — The CPU0 sleeping state.
    0=AWAKE (the CPU is not sleeping.); 1=SLEEPING (the CPU is sleeping.)
{0x920+4i} BOOT_SEED_REG{i} (i=0..7) — boot seed (256-bit random value)
{0x940+4i} HMAC_REG{i} (i=0..7) — HMAC
0x960 BOOT_LOCK — Control write access to boot seed security registers.
  [1] LOCK_HMAC — Control write access to HMAC_REG registers.
    1=LOCK (write access to all 8 registers HMAC_REG is locked. This register is write once.)
  [0] LOCK_BOOT_SEED — Control write access to BOOT_SEED_REG registers.
    1=LOCK (write access to all 8 registers BOOT_SEED_REG is locked. This register is write once.)
0xA18 CLOCK_CTRL reset 0x1 — Various system clock controls : Flash clock (48 MHz) control, clocks to Frequency Measures
  [all] fields
    0=DISABLE (The clock is not enabled.); 1=ENABLE (The clock is enabled.)
  [9] PLU_DEGLITCH_CLK_ENA — Enable clocks FRO_1MHz and FRO_12MHz for PLU deglitching.
  [8] XO_CAL_CLK_ENA — Enable clock for cristal oscilator calibration.
  [7] ANA_FRO12M_CLK_ENA — Enable FRO 12MHz clock for analog control of the FRO 192MHz.
  [6] FRO1MHZ_CLK_ENA — Enable FRO 1MHz clock for clock muxing in clock gen.
  [5] CLKIN_ENA — Enable clock_in clock for clock module.
  [4] FRO_HF_FREQM_ENA — Enable FRO 96MHz clock for Frequency Measure module.
  [3] FRO12MHZ_FREQM_ENA — Enable FRO 12MHz clock for Frequency Measure module.
  [2] FRO1MHZ_UTICK_ENA — Enable FRO 1MHz clock for Frequency Measure module and for UTICK.
  [1] XTAL32MHZ_FREQM_ENA — Enable XTAL32MHz clock for Frequency Measure module.
0xB10 COMP_INT_CTRL — Comparator Interrupt control
  [5] INT_SOURCE — Select which Analog comparator output (filtered our un-filtered) is used for interrupt detection.
    0=FILTER_INT (Select Analog Comparator filtered output as input for interrupt detection.); 1=RAW_INT (Select Analog Comparator raw output (unfiltered) as input for interrupt detection. Must be used when Analog comparator is used as wake up source in Power down mode.)
  [4:2] INT_CTRL — Comparator interrupt type selector:.
    0=EDGE_DISABLE (The analog comparator interrupt edge sensitive is disabled.); 1=LVL_DISABLE (The analog comparator interrupt level sensitive is disabled.); 2=EDGE_RISING (analog comparator interrupt is rising edge sensitive.); 3=LVL_HIGH (Analog Comparator interrupt is high level sensitive.); 4=EDGE_FALLING (analog comparator interrupt is falling edge sensitive.); 5=LVL_LOW (Analog Comparator interrupt is low level sensitive.); 6=EDGE_BOTH (analog comparator interrupt is rising and falling edge sensitive.); 7=LVL_DIS2 (The analog comparator interrupt level sensitive is disabled.)
  [1] INT_CLEAR — Analog Comparator interrupt clear.
    0=NONE (No effect.); 1=CLEAR (Clear the interrupt. Self-cleared bit.)
  [0] INT_ENABLE — Analog Comparator interrupt enable control:.
    0=INT_DISABLE (interrupt disable.); 1=INT_ENABLE (interrupt enable.)
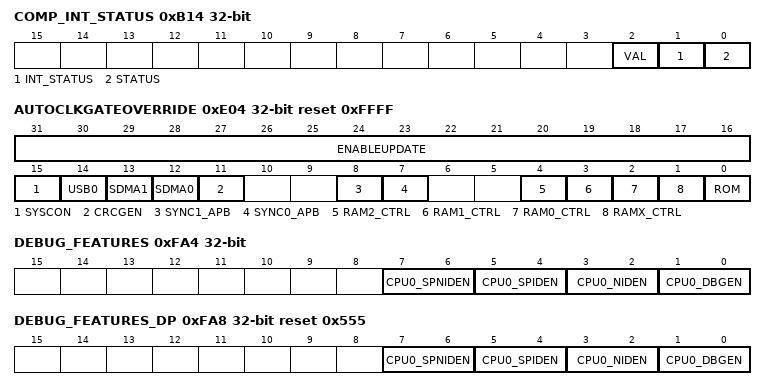
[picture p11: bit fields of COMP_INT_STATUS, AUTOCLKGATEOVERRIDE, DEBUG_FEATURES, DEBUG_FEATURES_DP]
0xB14 COMP_INT_STATUS — Comparator Interrupt status
  [2] VAL ro — comparator analog output.
    0=SMALLER (P+ is smaller than P-.); 1=GREATER (P+ is greater than P-.)
  [1] INT_STATUS ro — Interrupt status AFTER Interrupt Enable.
    0=NO_INT (no interrupt pending.); 1=PENDING (interrupt pending.)
  [0] STATUS ro — Interrupt status BEFORE Interrupt Enable.
    values as INT_STATUS
0xE04 AUTOCLKGATEOVERRIDE reset 0xFFFF — Control automatic clock gating
  [31:16] ENABLEUPDATE wo — The value 0xC0DE must be written for AUTOCLKGATEOVERRIDE registers fields updates to have effect.
    0=DISABLE (Bit Fields 0 - 15 of this register are not updated); 0xC0DE=ENABLE (Bit Fields 0 - 15 of this register are updated)
  [15] SYSCON — Control automatic clock gating of synchronous system controller registers bank.
    0=DISABLE (Automatic clock gating is not overridden.); 1=ENABLE (Automatic clock gating is overridden (Clock gating is disabled).)
  [14] USB0 — Control automatic clock gating of USB controller.
    values as SYSCON
  [13] SDMA1 — Control automatic clock gating of DMA1 controller.
    values as SYSCON
  [12] SDMA0 — Control automatic clock gating of DMA0 controller.
    values as SYSCON
  [11] CRCGEN — Control automatic clock gating of CRCGEN controller.
    values as SYSCON
  [8] SYNC1_APB — Control automatic clock gating of synchronous bridge controller 1.
    values as SYSCON
  [7] SYNC0_APB — Control automatic clock gating of synchronous bridge controller 0.
    values as SYSCON
  [4] RAM2_CTRL — Control automatic clock gating of RAM2 controller.
    values as SYSCON
  [3] RAM1_CTRL — Control automatic clock gating of RAM1 controller.
    values as SYSCON
  [2] RAM0_CTRL — Control automatic clock gating of RAM0 controller.
    values as SYSCON
  [1] RAMX_CTRL — Control automatic clock gating of RAMX controller.
    values as SYSCON
  [0] ROM — Control automatic clock gating of ROM controller.
    values as SYSCON
0xE08 GPIOPSYNC — Enable bypass of the first stage of synchonization inside GPIO_INT module
  [0] PSYNC — Enable bypass of the first stage of synchonization inside GPIO_INT module.
    0=USED (use the first stage of synchonization inside GPIO_INT module.); 1=BYPASS (bypass of the first stage of synchonization inside GPIO_INT module.)
0xF88 HASHRESTHWKEY rw-once — Controls whether the HASH AES hardware secret key is restricted to use by secure code
  [31:0] UNLOCKCODE — Code value that controls whether HASH AES hardware secret key is unlocked
    0xC33CA55A=UNLOCK (HASH AES hardware secret key is unlocked for use by non-secure code. Any other value means that the hardware secret key is restricted to use by secure code only.)
0xFA0 DEBUG_LOCK_EN reset 0x5 — Control write access to security registers.
  [3:0] LOCK_ALL
    0=DISABLE (Any other value than b1010: disable write access to all registers.); 10=ENABLE (1010: Enable write access to all registers.)
0xFA4 DEBUG_FEATURES — Cortex debug features control.
  [all] fields
    1=DISABLE (Any other value than b10: invasive debug is disable.); 2=ENABLE (10: Invasive debug is enabled.)
  [7:6] CPU0_SPNIDEN — CPU0 Secure Non Invasive debug control:.
  [5:4] CPU0_SPIDEN — CPU0 Secure Invasive debug control:.
  [3:2] CPU0_NIDEN — CPU0 Non Invasive debug control:.
  [1:0] CPU0_DBGEN — CPU0 Invasive debug control:.
0xFA8 DEBUG_FEATURES_DP reset 0x555 — Cortex debug features control. (duplicate)
  [all] fields
    values as the fields of DEBUG_FEATURES
  [7:6] CPU0_SPNIDEN — CPU0 Secure Non Invasive debug control:.
  [5:4] CPU0_SPIDEN — CPU0 Secure Invasive debug control:.
  [3:2] CPU0_NIDEN — CPU0 Non Invasive debug control:.
  [1:0] CPU0_DBGEN — CPU0 (CPU0) Invasive debug control:.
0xFB4 SWD_ACCESS_CPU0 — This register is used by ROM during DEBUG authentication mechanism to enable debug access port for CPU0.
  [31:0] SEC_CODE — CPU0 SWD-AP: 0x12345678.
    0=DISABLE (CPU0 DAP is not allowed. Reading back register will be read as 0x5.); 0x12345678=ENABLE (Value to write to enable CPU0 SWD access. Reading back register will be read as 0xA.)
0xFBC KEY_BLOCK wo reset 0x3CC35AA5 — block quiddikey/PUF all index.
  [31:0] KEY_BLOCK — Write a value to block quiddikey/PUF all index.
0xFC0 DEBUG_AUTH_BEACON — Debug authentication BEACON register
  [31:0] BEACON — Set by the debug authentication code in ROM to pass the debug beacons (Credential Beacon and Authentication Beacon) to application code.
0xFF8 DEVICE_ID0 ro — Device ID
  [23:20] ROM_REV_MINOR — ROM revision.
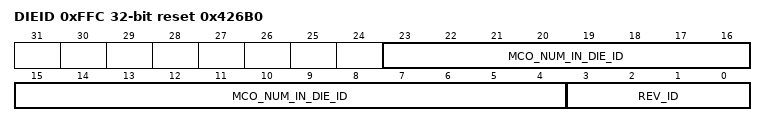
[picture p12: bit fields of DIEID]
0xFFC DIEID ro reset 0x426B0 — Chip revision ID and Number
  [23:4] MCO_NUM_IN_DIE_ID — Chip Number 0x426B.
  [3:0] REV_ID — Chip Metal Revision ID.
